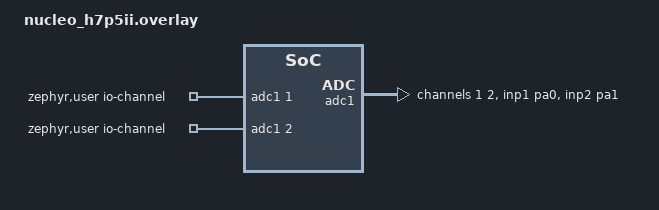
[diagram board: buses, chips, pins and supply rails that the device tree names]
/* SPDX-FileCopyrightText: Copyright (c) 2026 STMicroelectronics
 * SPDX-License-Identifier: Apache-2.0
 */

/ {
	zephyr,user {
		io-channels = <&adc1 1>, <&adc1 2>;
	};
};

&adc1 {
	pinctrl-0 = <&adc1_inp1_pa0 &adc1_inp2_pa1>;
	pinctrl-names = "default";

	#address-cells = <1>;
	#size-cells = <0>;

	channel@1 {
		reg = <1>;
		zephyr,gain = "ADC_GAIN_1";
		zephyr,reference = "ADC_REF_INTERNAL";
		zephyr,acquisition-time = <ADC_ACQ_TIME_DEFAULT>;
		zephyr,resolution = <12>;
	};

	channel@2 {
		reg = <2>;
		zephyr,gain = "ADC_GAIN_1";
		zephyr,reference = "ADC_REF_INTERNAL";
		zephyr,acquisition-time = <ADC_ACQ_TIME_DEFAULT>;
		zephyr,resolution = <12>;
	};

	status = "okay";
};
